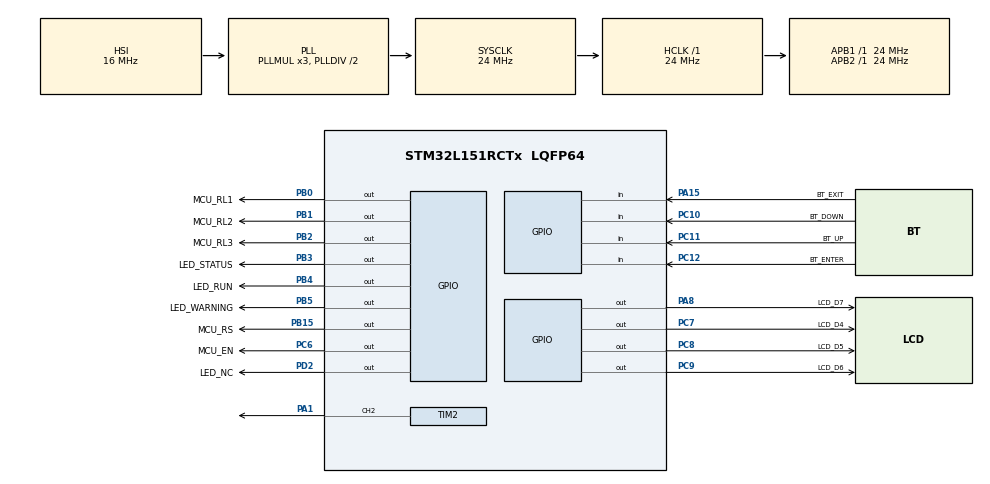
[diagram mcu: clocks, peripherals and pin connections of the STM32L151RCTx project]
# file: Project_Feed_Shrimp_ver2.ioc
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IWDG.Prescaler=IWDG_PRESCALER_256
IWDG.Reload=312
Mcu.Family=STM32L1
Mcu.Name=STM32L151RCTx
Mcu.Package=LQFP64
NVIC.PriorityGroup=NVIC_PRIORITYGROUP_4
PA1.Signal=S_TIM2_CH2
PA13.Mode=Serial_Wire
PA13.Signal=SYS_JTMS-SWDIO
PA14.Mode=Serial_Wire
PA14.Signal=SYS_JTCK-SWCLK
PA15.GPIO_Label=BT_EXIT
PA15.Signal=GPIO_Input
PA8.GPIO_Label=LCD_D7
PA8.Signal=GPIO_Output
PB0.GPIO_Label=MCU_RL1
PB0.GPIO_PuPd=GPIO_PULLUP
PB0.PinState=GPIO_PIN_SET
PB0.Signal=GPIO_Output
PB1.GPIO_Label=MCU_RL2
PB1.Signal=GPIO_Output
PB15.GPIO_Label=MCU_RS
PB15.Signal=GPIO_Output
PB2.GPIO_Label=MCU_RL3
PB2.Signal=GPIO_Output
PB3.GPIO_Label=LED_STATUS
PB3.Signal=GPIO_Output
PB4.GPIO_Label=LED_RUN
PB4.Signal=GPIO_Output
PB5.GPIO_Label=LED_WARNING
PB5.Signal=GPIO_Output
PC10.GPIO_Label=BT_DOWN
PC10.Signal=GPIO_Input
PC11.GPIO_Label=BT_UP
PC11.Signal=GPIO_Input
PC12.GPIO_Label=BT_ENTER
PC12.Signal=GPIO_Input
PC14-OSC32_IN.Mode=LSE-External-Oscillator
PC14-OSC32_IN.Signal=RCC_OSC32_IN
PC15-OSC32_OUT.Mode=LSE-External-Oscillator
PC15-OSC32_OUT.Signal=RCC_OSC32_OUT
PC6.GPIO_Label=MCU_EN
PC6.Signal=GPIO_Output
PC7.GPIO_Label=LCD_D4
PC7.Signal=GPIO_Output
PC8.GPIO_Label=LCD_D5
PC8.Signal=GPIO_Output
PC9.GPIO_Label=LCD_D6
PC9.Signal=GPIO_Output
PD2.GPIO_Label=LED_NC
PD2.Signal=GPIO_Output
ProjectManager.HeapSize=0x200
ProjectManager.StackSize=0x400
ProjectManager.TargetToolchain=EWARM V8.32
RCC.AHBFreq_Value=24000000
RCC.APB1Freq_Value=24000000
RCC.APB1TimFreq_Value=24000000
RCC.APB2Freq_Value=24000000
RCC.APB2TimFreq_Value=24000000
RCC.HCLKFreq_Value=24000000
RCC.HSE_VALUE=24000000
RCC.HSI_VALUE=16000000
RCC.MSI_VALUE=2097000
RCC.RTCClockSelection=RCC_RTCCLKSOURCE_LSE
RCC.RTCClockSelectionVirtual=RCC_RTCCLKSOURCE_LSE
RCC.SYSCLKFreq_VALUE=24000000
RCC.SYSCLKSource=RCC_SYSCLKSOURCE_PLLCLK
RCC.VCOOutputFreq_Value=48000000
SH.S_TIM2_CH2.0=TIM2_CH2,PWM Generation2 CH2
TIM2.AutoReloadPreload=TIM_AUTORELOAD_PRELOAD_DISABLE
TIM2.Channel-PWM\ Generation2\ CH2=TIM_CHANNEL_2
TIM2.OCMode_PWM-PWM\ Generation2\ CH2=TIM_OCMODE_PWM1
TIM2.Period=99
TIM2.Prescaler=23
VP_IWDG_VS_IWDG.Mode=IWDG_Activate
VP_RTC_VS_RTC_Activate.Mode=RTC_Enabled
VP_RTC_VS_RTC_Calendar.Mode=RTC_Calendar
VP_TIM2_VS_ClockSourceINT.Mode=Internal
board=custom

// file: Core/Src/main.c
/* USER CODE BEGIN Header */
/**
  ******************************************************************************
  * @file           : main.c
  * @brief          : Main program body
  ******************************************************************************
  * @attention
  *
  * Copyright (c) 2023 STMicroelectronics.
  * All rights reserved.
  *
  * This software is licensed under terms that can be found in the LICENSE file
  * in the root directory of this software component.
  * If no LICENSE file comes with this software, it is provided AS-IS.
  *
  ******************************************************************************
  */
/* USER CODE END Header */
#include "main.h"
#include "iwdg.h"
#include "rtc.h"
#include "tim.h"
#include "gpio.h"

/* USER CODE BEGIN Includes */
#include "user_app_comm.h"
/* USER CODE END Includes */

void SystemClock_Config(void);

int main(void)
{

  /* MCU Configuration--------------------------------------------------------*/

  /* Reset of all peripherals, Initializes the Flash interface and the Systick. */
  HAL_Init();

  /* Configure the system clock */
  SystemClock_Config();

  /* Initialize all configured peripherals */
  MX_GPIO_Init();
  MX_RTC_Init();
  MX_IWDG_Init();
  MX_TIM2_Init();
  /* USER CODE BEGIN 2 */

//  HAL_Delay(1000);
//
//while(1)
//{}
  Main_Task();
  /* USER CODE END 2 */

  /* Infinite loop */
  while (1)
  {

  }
}

void SystemClock_Config(void)
{
  RCC_OscInitTypeDef RCC_OscInitStruct = {0};
  RCC_ClkInitTypeDef RCC_ClkInitStruct = {0};
  RCC_PeriphCLKInitTypeDef PeriphClkInit = {0};

  /** Configure the main internal regulator output voltage
  */
  __HAL_PWR_VOLTAGESCALING_CONFIG(PWR_REGULATOR_VOLTAGE_SCALE1);

  /** Initializes the RCC Oscillators according to the specified parameters
  * in the RCC_OscInitTypeDef structure.
  */
  RCC_OscInitStruct.OscillatorType = RCC_OSCILLATORTYPE_HSI|RCC_OSCILLATORTYPE_LSI
                              |RCC_OSCILLATORTYPE_LSE;
  RCC_OscInitStruct.LSEState = RCC_LSE_ON;
  RCC_OscInitStruct.HSIState = RCC_HSI_ON;
  RCC_OscInitStruct.HSICalibrationValue = RCC_HSICALIBRATION_DEFAULT;
  RCC_OscInitStruct.LSIState = RCC_LSI_ON;
  RCC_OscInitStruct.PLL.PLLState = RCC_PLL_ON;
  RCC_OscInitStruct.PLL.PLLSource = RCC_PLLSOURCE_HSI;
  RCC_OscInitStruct.PLL.PLLMUL = RCC_PLL_MUL3;
  RCC_OscInitStruct.PLL.PLLDIV = RCC_PLL_DIV2;
  if (HAL_RCC_OscConfig(&RCC_OscInitStruct) != HAL_OK)
  {
    Error_Handler();
  }

  /** Initializes the CPU, AHB and APB buses clocks
  */
  RCC_ClkInitStruct.ClockType = RCC_CLOCKTYPE_HCLK|RCC_CLOCKTYPE_SYSCLK
                              |RCC_CLOCKTYPE_PCLK1|RCC_CLOCKTYPE_PCLK2;
  RCC_ClkInitStruct.SYSCLKSource = RCC_SYSCLKSOURCE_PLLCLK;
  RCC_ClkInitStruct.AHBCLKDivider = RCC_SYSCLK_DIV1;
  RCC_ClkInitStruct.APB1CLKDivider = RCC_HCLK_DIV1;
  RCC_ClkInitStruct.APB2CLKDivider = RCC_HCLK_DIV1;

  if (HAL_RCC_ClockConfig(&RCC_ClkInitStruct, FLASH_LATENCY_1) != HAL_OK)
  {
    Error_Handler();
  }
  PeriphClkInit.PeriphClockSelection = RCC_PERIPHCLK_RTC;
  PeriphClkInit.RTCClockSelection = RCC_RTCCLKSOURCE_LSE;
  if (HAL_RCCEx_PeriphCLKConfig(&PeriphClkInit) != HAL_OK)
  {
    Error_Handler();
  }
}

void Error_Handler(void)
{
  __disable_irq();
  while (1)
  {
  }
}
